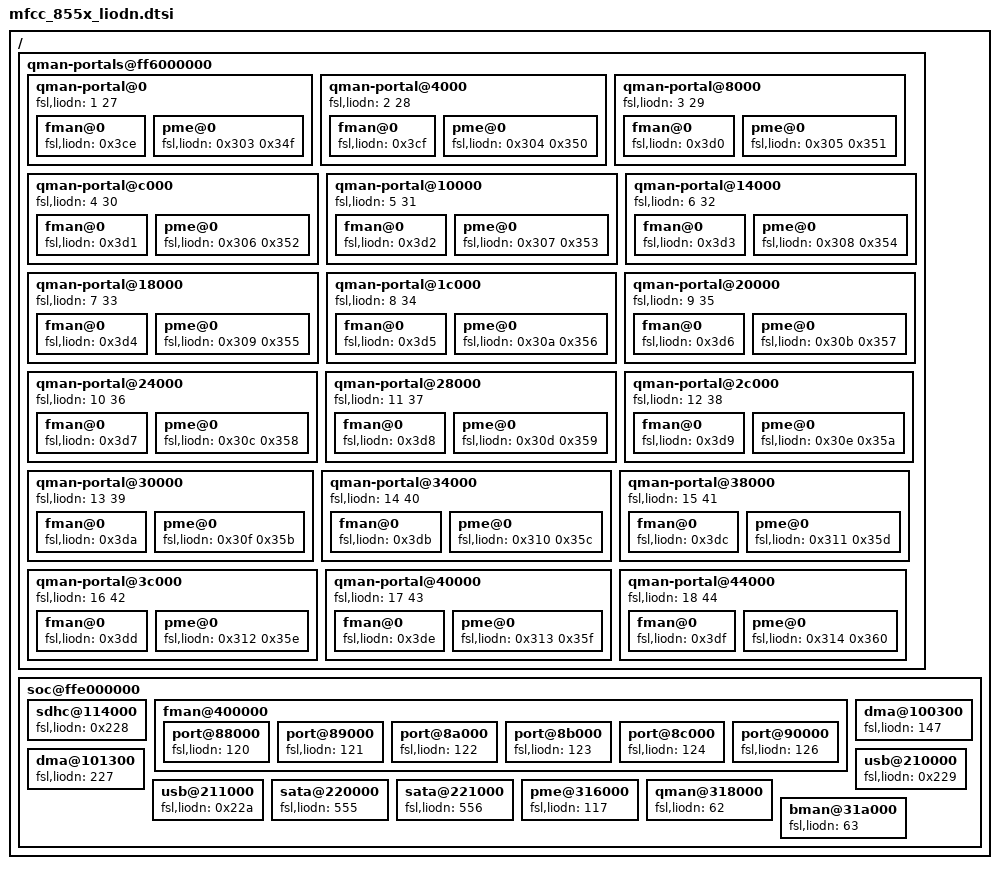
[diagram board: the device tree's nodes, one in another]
/ {
	qman-portals@ff6000000 {
		qman-portal@0 {
			fsl,liodn = <1 27>;
			fman@0 {
				fsl,liodn = <0x3ce>;
			};
			pme@0 {
				fsl,liodn = <0x303 0x34f>;
			};
		};
		qman-portal@4000 {
			fsl,liodn = <2 28>;
			fman@0 {
				fsl,liodn = <0x3cf>;
			};
			pme@0 {
				fsl,liodn = <0x304 0x350>;
			};
		};
		qman-portal@8000 {
			fsl,liodn = <3 29>;
			fman@0 {
				fsl,liodn = <0x3d0>;
			};
			pme@0 {
				fsl,liodn = <0x305 0x351>;
			};
		};
		qman-portal@c000 {
			fsl,liodn = <4 30>;
			fman@0 {
				fsl,liodn = <0x3d1>;
			};
			pme@0 {
				fsl,liodn = <0x306 0x352>;
			};
		};
		qman-portal@10000 {
			fsl,liodn = <5 31>;
			fman@0 {
				fsl,liodn = <0x3d2>;
			};
			pme@0 {
				fsl,liodn = <0x307 0x353>;
			};
		};
		qman-portal@14000 {
			fsl,liodn = <6 32>;
			fman@0 {
				fsl,liodn = <0x3d3>;
			};
			pme@0 {
				fsl,liodn = <0x308 0x354>;
			};
		};
		qman-portal@18000 {
			fsl,liodn = <7 33>;
			fman@0 {
				fsl,liodn = <0x3d4>;
			};
			pme@0 {
				fsl,liodn = <0x309 0x355>;
			};
		};
		qman-portal@1c000 {
			fsl,liodn = <8 34>;
			fman@0 {
				fsl,liodn = <0x3d5>;
			};
			pme@0 {
				fsl,liodn = <0x30a 0x356>;
			};
		};
		qman-portal@20000 {
			fsl,liodn = <9 35>;
			fman@0 {
				fsl,liodn = <0x3d6>;
			};
			pme@0 {
				fsl,liodn = <0x30b 0x357>;
			};
		};
		qman-portal@24000 {
			fsl,liodn = <10 36>;
			fman@0 {
				fsl,liodn = <0x3d7>;
			};
			pme@0 {
				fsl,liodn = <0x30c 0x358>;
			};
		};
		qman-portal@28000 {
			fsl,liodn = <11 37>;
			fman@0 {
				fsl,liodn = <0x3d8>;
			};
			pme@0 {
				fsl,liodn = <0x30d 0x359>;
			};
		};
		qman-portal@2c000 {
			fsl,liodn = <12 38>;
			fman@0 {
				fsl,liodn = <0x3d9>;
			};
			pme@0 {
				fsl,liodn = <0x30e 0x35a>;
			};
		};
		qman-portal@30000 {
			fsl,liodn = <13 39>;
			fman@0 {
				fsl,liodn = <0x3da>;
			};
			pme@0 {
				fsl,liodn = <0x30f 0x35b>;
			};
		};
		qman-portal@34000 {
			fsl,liodn = <14 40>;
			fman@0 {
				fsl,liodn = <0x3db>;
			};
			pme@0 {
				fsl,liodn = <0x310 0x35c>;
			};
		};
		qman-portal@38000 {
			fsl,liodn = <15 41>;
			fman@0 {
				fsl,liodn = <0x3dc>;
			};
			pme@0 {
				fsl,liodn = <0x311 0x35d>;
			};
		};
		qman-portal@3c000 {
			fsl,liodn = <16 42>;
			fman@0 {
				fsl,liodn = <0x3dd>;
			};
			pme@0 {
				fsl,liodn = <0x312 0x35e>;
			};
		};
		qman-portal@40000 {
			fsl,liodn = <17 43>;
			fman@0 {
				fsl,liodn = <0x3de>;
			};
			pme@0 {
				fsl,liodn = <0x313 0x35f>;
			};
		};
		qman-portal@44000 {
			fsl,liodn = <18 44>;
			fman@0 {
				fsl,liodn = <0x3df>;
			};
			pme@0 {
				fsl,liodn = <0x314 0x360>;
			};
		};
	};

	soc@ffe000000 {
		sdhc@114000 {
			fsl,liodn = <0x228>;
		};
		fman@400000 {
			port@88000 { /* fman0_rx0 */
				fsl,liodn = <120>;
			};
			port@89000 { /* fman0_rx1 */
				fsl,liodn = <121>;
			};
			port@8a000 { /* fman0_rx2 */
				fsl,liodn = <122>;
			};
			port@8b000 { /* fman0_rx3 */
				fsl,liodn = <123>;
			};
			port@8c000 { /* fman0_rx4 */
				fsl,liodn = <124>;
			};
			port@90000 { /* fman0_10g_rx0 */
				fsl,liodn = <126>;
			};
		};
		dma@100300 {
			fsl,liodn = <147>;
		};
		dma@101300 {
			fsl,liodn = <227>;
		};
		usb@210000 {
			fsl,liodn = <0x229>;
		};
		usb@211000 {
			fsl,liodn = <0x22a>;
		};
		sata@220000 {
			fsl,liodn = <555>;
		};
		sata@221000 {
			fsl,liodn = <556>;
		};
		pme@316000 {
			fsl,liodn = <117>;
		};
		qman@318000 {
			fsl,liodn = <62>;
		};
		bman@31a000 {
			fsl,liodn = <63>;
		};
	};
};
